# MB9BFD1xT register map
File version: 1.7
Registers are 32-bit, read-write, reset 0x0 unless marked. A register's access mark holds for its fields unless they carry their own. Offsets are from the block's base; [hi:lo] are bit positions; {n}, {i} and the like mark numbered series; 'fields as' and 'values as' point back to an identical list.

## GPIO — General-purpose I/O ports
Base 0x40033000
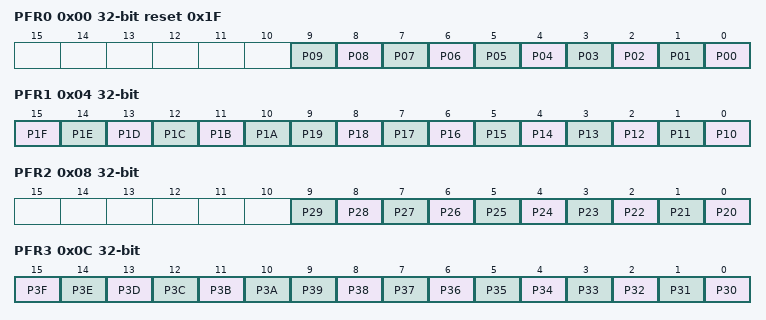
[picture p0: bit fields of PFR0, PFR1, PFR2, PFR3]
0x00 PFR0 reset 0x1F — Port function setting register 0
  [n] P{n:02} (n=0..9) — Bit{n} of PFR0
0x04 PFR1 — Port function setting register 1
  [15] P1F — Bit15 of PFR1
  [14] P1E — Bit14 of PFR1
  [13] P1D — Bit13 of PFR1
  [12] P1C — Bit12 of PFR1
  [11] P1B — Bit11 of PFR1
  [10] P1A — Bit10 of PFR1
  [n-10] P{n} (n=10..19) — Bit{n-10} of PFR1
0x08 PFR2 — Port function setting register 2
  [n-20] P{n} (n=20..29) — Bit{n-20} of PFR2
0x0C PFR3 — Port function setting register 3
  [15] P3F — Bit15 of PFR3
  [14] P3E — Bit14 of PFR3
  [13] P3D — Bit13 of PFR3
  [12] P3C — Bit12 of PFR3
  [11] P3B — Bit11 of PFR3
  [10] P3A — Bit10 of PFR3
  [n-30] P{n} (n=30..39) — Bit{n-30} of PFR3
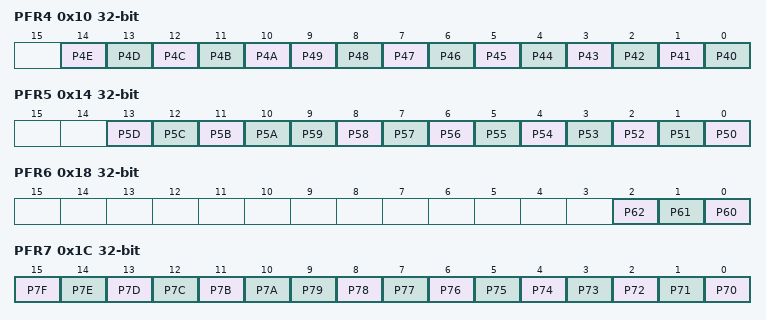
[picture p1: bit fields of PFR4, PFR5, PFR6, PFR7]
0x10 PFR4 — Port function setting register 4
  [14] P4E — Bit14 of PFR4
  [13] P4D — Bit13 of PFR4
  [12] P4C — Bit12 of PFR4
  [11] P4B — Bit11 of PFR4
  [10] P4A — Bit10 of PFR4
  [n-40] P{n} (n=40..49) — Bit{n-40} of PFR4
0x14 PFR5 — Port function setting register 5
  [13] P5D — Bit13 of PFR5
  [12] P5C — Bit12 of PFR5
  [11] P5B — Bit11 of PFR5
  [10] P5A — Bit10 of PFR5
  [n-50] P{n} (n=50..59) — Bit{n-50} of PFR5
0x18 PFR6 — Port function setting register 6
  [2] P62 — Bit2 of PFR6
  [1] P61 — Bit1 of PFR6
  [0] P60 — Bit0 of PFR6
0x1C PFR7 — Port function setting register 7
  [15] P7F — Bit15 of PFR7
  [14] P7E — Bit14 of PFR7
  [13] P7D — Bit13 of PFR7
  [12] P7C — Bit12 of PFR7
  [11] P7B — Bit11 of PFR7
  [10] P7A — Bit10 of PFR7
  [n-70] P{n} (n=70..79) — Bit{n-70} of PFR7
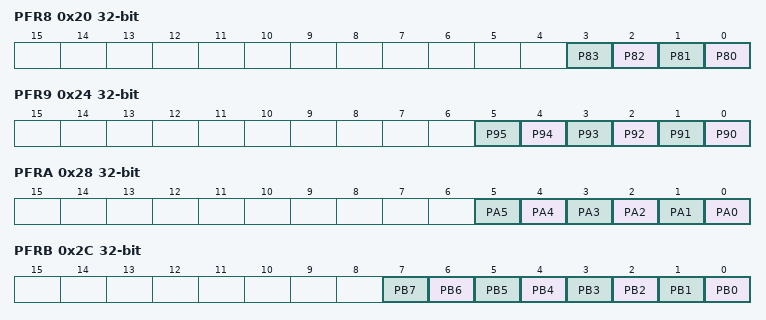
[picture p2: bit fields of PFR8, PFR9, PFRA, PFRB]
0x20 PFR8 — Port function setting register 8
  [n-80] P{n} (n=80..83) — Bit{n-80} of PFR8
0x24 PFR9 — Port function setting register 9
  [n-90] P{n} (n=90..95) — Bit{n-90} of PFR9
0x28 PFRA — Port function setting register A
  [n] PA{n} (n=0..5) — Bit{n} of PFRA
0x2C PFRB — Port function setting register B
  [n] PB{n} (n=0..7) — Bit{n} of PFRB
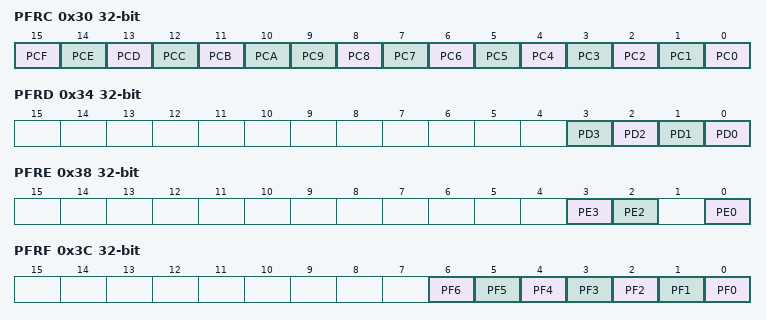
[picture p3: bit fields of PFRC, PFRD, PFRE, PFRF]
0x30 PFRC — Port function setting register C
  [15] PCF — Bit15 of PFRC
  [14] PCE — Bit14 of PFRC
  [13] PCD — Bit13 of PFRC
  [12] PCC — Bit12 of PFRC
  [11] PCB — Bit11 of PFRC
  [10] PCA — Bit10 of PFRC
  [n] PC{n} (n=0..9) — Bit{n} of PFRC
0x34 PFRD — Port function setting register D
  [n] PD{n} (n=0..3) — Bit{n} of PFRD
0x38 PFRE (reset mask 0xB) — Port function setting register E
  [3] PE3 — Bit3 of PFRE
  [2] PE2 — Bit2 of PFRE
  [0] PE0 — Bit0 of PFRE
0x3C PFRF — Port function setting register F
  [n] PF{n} (n=0..6) — Bit{n} of PFRF
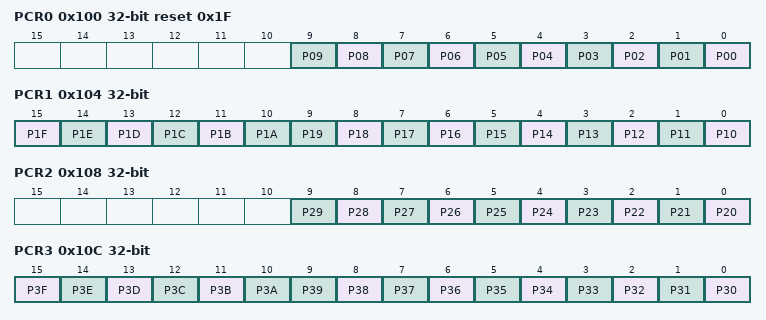
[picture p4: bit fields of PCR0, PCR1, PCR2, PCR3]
0x100 PCR0 reset 0x1F — Pull-up Setting Register 0
  [n] P{n:02} (n=0..9) — Bit{n} of PFR0
0x104 PCR1 — Pull-up Setting Register 1
  fields as PFR1
0x108 PCR2 — Pull-up Setting Register 2
  [n-20] P{n} (n=20..29) — Bit{n-20} of PFR2
0x10C PCR3 — Pull-up Setting Register 3
  fields as PFR3
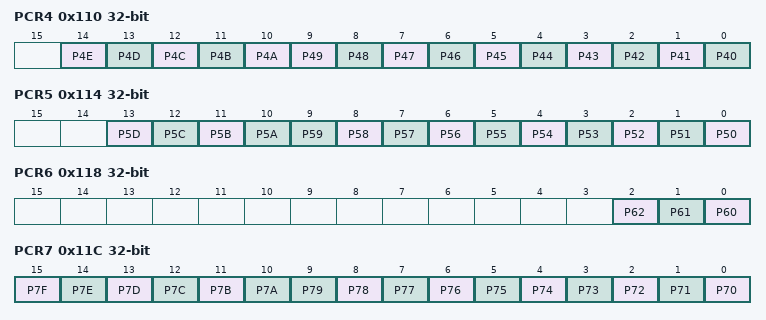
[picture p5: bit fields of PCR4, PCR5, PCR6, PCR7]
0x110 PCR4 — Pull-up Setting Register 4
  fields as PFR4
0x114 PCR5 — Pull-up Setting Register 5
  fields as PFR5
0x118 PCR6 — Pull-up Setting Register 6
  fields as PFR6
0x11C PCR7 — Pull-up Setting Register 7
  fields as PFR7
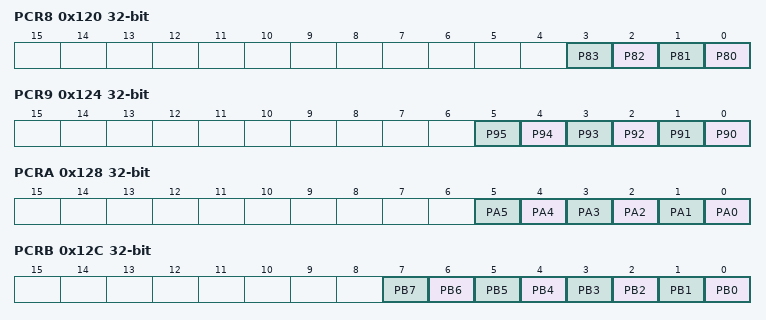
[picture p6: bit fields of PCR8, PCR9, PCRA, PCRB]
0x120 PCR8 — Pull-up Setting Register 8
  [n-80] P{n} (n=80..83) — Bit{n-80} of PFR8
0x124 PCR9 — Pull-up Setting Register 9
  [n-90] P{n} (n=90..95) — Bit{n-90} of PFR9
0x128 PCRA — Pull-up Setting Register A
  [n] PA{n} (n=0..5) — Bit{n} of PFRA
0x12C PCRB — Pull-up Setting Register B
  [n] PB{n} (n=0..7) — Bit{n} of PFRB
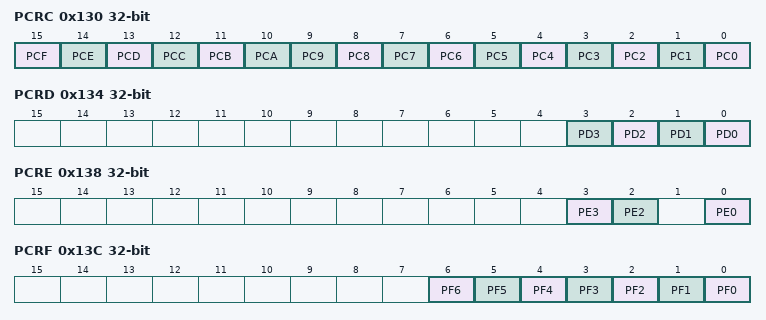
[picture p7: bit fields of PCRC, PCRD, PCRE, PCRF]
0x130 PCRC — Pull-up Setting Register C
  fields as PFRC
0x134 PCRD — Pull-up Setting Register D
  [n] PD{n} (n=0..3) — Bit{n} of PFRD
0x138 PCRE (reset mask 0xB) — Pull-up Setting Register E
  fields as PFRE
0x13C PCRF — Pull-up Setting Register F
  [n] PF{n} (n=0..6) — Bit{n} of PFRF
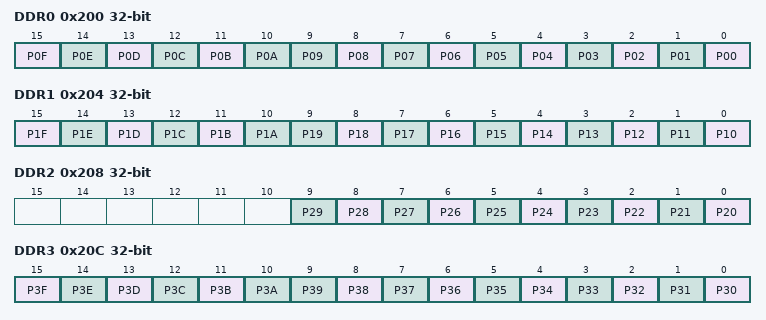
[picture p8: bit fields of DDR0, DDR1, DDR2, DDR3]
0x200 DDR0 — Port input/output direction setting register 0
  [15] P0F — Bit15 of DDR0
  [14] P0E — Bit14 of DDR0
  [13] P0D — Bit13 of DDR0
  [12] P0C — Bit12 of DDR0
  [11] P0B — Bit11 of DDR0
  [10] P0A — Bit10 of DDR0
  [n] P{n:02} (n=0..9) — Bit{n} of DDR0
0x204 DDR1 — Port input/output direction setting register 1
  fields as PFR1
0x208 DDR2 — Port input/output direction setting register 2
  [n-20] P{n} (n=20..29) — Bit{n-20} of PFR2
0x20C DDR3 — Port input/output direction setting register 3
  fields as PFR3
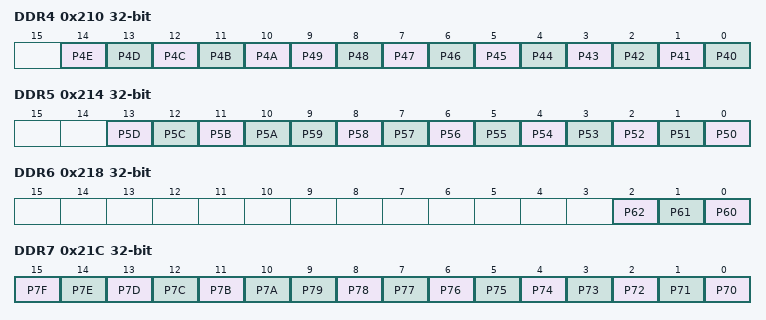
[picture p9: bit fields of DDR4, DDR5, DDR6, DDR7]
0x210 DDR4 — Port input/output direction setting register 4
  fields as PFR4
0x214 DDR5 — Port input/output direction setting register 5
  fields as PFR5
0x218 DDR6 — Port input/output direction setting register 6
  fields as PFR6
0x21C DDR7 — Port input/output direction setting register 7
  fields as PFR7
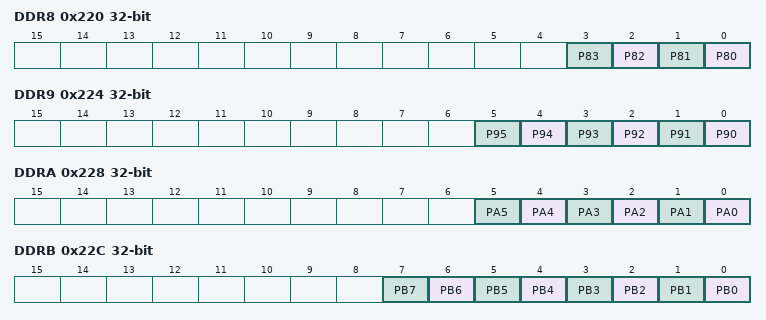
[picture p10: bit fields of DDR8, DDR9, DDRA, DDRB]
0x220 DDR8 — Port input/output direction setting register 8
  [n-80] P{n} (n=80..83) — Bit{n-80} of PFR8
0x224 DDR9 — Port input/output direction setting register 9
  [n-90] P{n} (n=90..95) — Bit{n-90} of PFR9
0x228 DDRA — Port input/output direction setting register A
  [n] PA{n} (n=0..5) — Bit{n} of PFRA
0x22C DDRB — Port input/output direction setting register B
  [n] PB{n} (n=0..7) — Bit{n} of PFRB
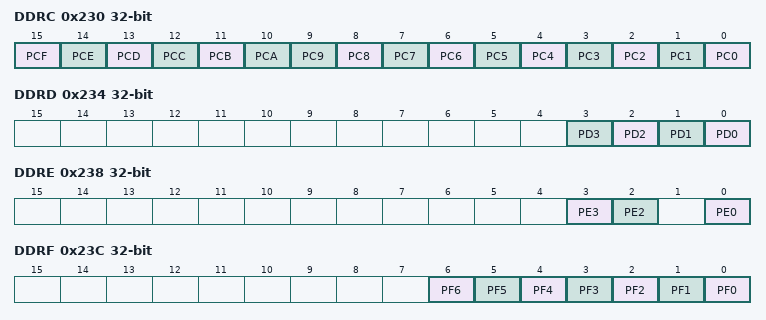
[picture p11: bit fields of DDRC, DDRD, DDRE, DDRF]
0x230 DDRC — Port input/output direction setting register C
  fields as PFRC
0x234 DDRD — Port input/output direction setting register D
  [n] PD{n} (n=0..3) — Bit{n} of PFRD
0x238 DDRE (reset mask 0xB) — Port input/output direction setting register E
  fields as PFRE
0x23C DDRF — Port input/output direction setting register F
  [n] PF{n} (n=0..6) — Bit{n} of PFRF
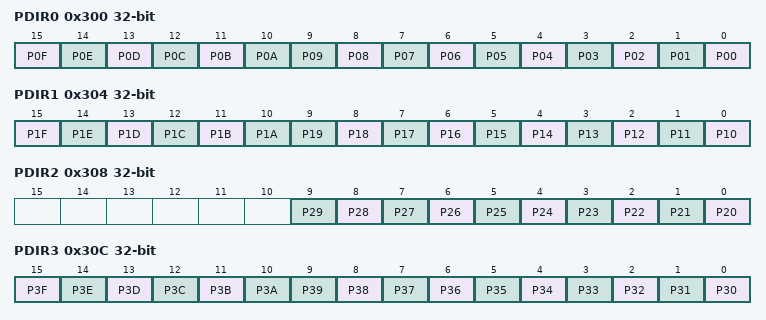
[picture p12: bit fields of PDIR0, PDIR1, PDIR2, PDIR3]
0x300 PDIR0 — Port input data register 0
  fields as DDR0
0x304 PDIR1 — Port input data register 1
  fields as PFR1
0x308 PDIR2 — Port input data register 2
  [n-20] P{n} (n=20..29) — Bit{n-20} of PFR2
0x30C PDIR3 — Port input data register 3
  fields as PFR3
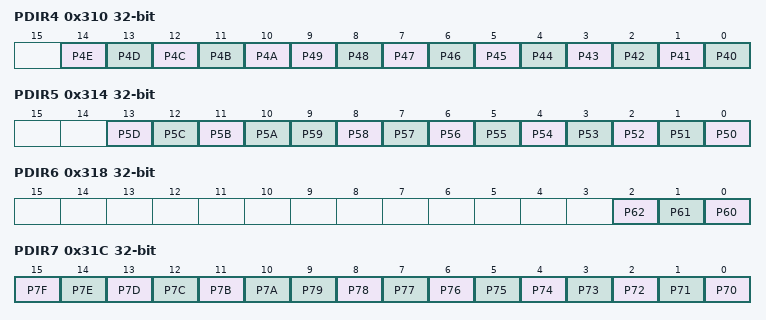
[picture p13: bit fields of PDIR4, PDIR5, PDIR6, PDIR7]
0x310 PDIR4 — Port input data register 4
  fields as PFR4
0x314 PDIR5 — Port input data register 5
  fields as PFR5
0x318 PDIR6 — Port input data register 6
  fields as PFR6
0x31C PDIR7 — Port input data register 7
  fields as PFR7
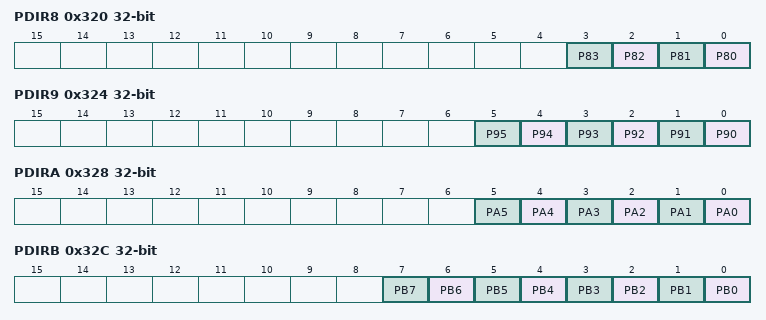
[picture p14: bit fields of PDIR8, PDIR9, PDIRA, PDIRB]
0x320 PDIR8 — Port input data register 8
  [n-80] P{n} (n=80..83) — Bit{n-80} of PFR8
0x324 PDIR9 — Port input data register 9
  [n-90] P{n} (n=90..95) — Bit{n-90} of PFR9
0x328 PDIRA — Port input data register A
  [n] PA{n} (n=0..5) — Bit{n} of PFRA
0x32C PDIRB — Port input data register B
  [n] PB{n} (n=0..7) — Bit{n} of PFRB
0x330 PDIRC — Port input data register C
  fields as PFRC
0x334 PDIRD — Port input data register D
  [n] PD{n} (n=0..3) — Bit{n} of PFRD
0x338 PDIRE (reset mask 0xB) — Port input data register E
  fields as PFRE
0x33C PDIRF — Port input data register F
  [n] PF{n} (n=0..6) — Bit{n} of PFRF
0x400 PDOR0 — Port output data register 0
  fields as DDR0
0x404 PDOR1 — Port output data register 1
  fields as PFR1
0x408 PDOR2 — Port output data register 2
  [n-20] P{n} (n=20..29) — Bit{n-20} of PFR2
0x40C PDOR3 — Port output data register 3
  fields as PFR3
0x410 PDOR4 — Port output data register 4
  fields as PFR4
0x414 PDOR5 — Port output data register 5
  fields as PFR5
0x418 PDOR6 — Port output data register 6
  fields as PFR6
0x41C PDOR7 — Port output data register 7
  fields as PFR7
0x420 PDOR8 — Port output data register 8
  [n-80] P{n} (n=80..83) — Bit{n-80} of PFR8
0x424 PDOR9 — Port output data register 9
  [n-90] P{n} (n=90..95) — Bit{n-90} of PFR9
0x428 PDORA — Port output data register A
  [n] PA{n} (n=0..5) — Bit{n} of PFRA
0x42C PDORB — Port output data register B
  [n] PB{n} (n=0..7) — Bit{n} of PFRB
0x430 PDORC — Port output data register C
  fields as PFRC
0x434 PDORD — Port output data register D
  [n] PD{n} (n=0..3) — Bit{n} of PFRD
0x438 PDORE (reset mask 0xB) — Port output data register E
  fields as PFRE
0x43C PDORF — Port output data register F
  [n] PF{n} (n=0..6) — Bit{n} of PFRF
0x500 ADE reset 0xFFFFFFFF — Analog input setting register
  [n] AN{n} (n=0..31) — Bit{n} of ADE
0x580 SPSR reset 0x5 — Special port setting register
  [5] USB1C — USBch1 pin setting bit
  [4] USB0C — USBch0 pin setting bit
  [2] MAINXC — Main clock(oscillation) pin setting bit
  [0] SUBXC — Sub clock(oscillation) pin setting bit
0x600 EPFR00 reset 0x30000 (reset mask 0x303022C7) — Extended pin function setting register 00
  [25] TRC1E — TRACED function select bit1
  [24] TRC0E — TRACED function select bit0
  [17] JTAGEN1S — JTAG function select bit1
  [16] JTAGEN0B — JTAG function select bit0
  [13] USBP1E — USBch1 function select bit
  [9] USBP0E — USBch0 function select bit
  [7:6] SUBOUTE — Sub clock divide output function select bit
  [2:1] CROUTE — Internal high-speed CR oscillation output function select bit
  [0] NMIS — NMIX function select bit
0x604 EPFR01 — Extended pin function setting register 01
  [3n+22:3n+20] IC{n:02}S (n=0..3) — IC{n:02} input select bit
  [19:18] FRCK0S — FRCK0 input select bit
  [17:16] DTTI0S — DTTIX0 input select bit
  [12] DTTI0C — DTTIX0 function select bit
  [2n+1:2n] RTO{n:02}E (n=0..5) — RTO{n:02}E output select bit
0x608 EPFR02 — Extended pin function setting register 02
  [3n-8:3n-10] IC{n}S (n=10..13) — IC{n} input select bit
  [19:18] FRCK1S — FRCK1 input select bit
  [17:16] DTTI1S — DTTIX1 input select bit
  [12] DTTI1C — DTTIX1 function select bit
  [2n-19:2n-20] RTO{n}E (n=10..15) — RTO{n}E output select bit
0x60C EPFR03 — Extended pin function setting register 03
  [3n-38:3n-40] IC{n}S (n=20..23) — IC{n} input select bit
  [19:18] FRCK2S — FRCK2 input select bit
  [17:16] DTTI2S — DTTIX2 input select bit
  [12] DTTI2C — DTTIX2 function select bit
  [2n-39:2n-40] RTO{n}E (n=20..25) — RTO{n}E output select bit
0x610 EPFR04 — Extended pin function setting register 04
  [8n+5:8n+4] TIOB{n}S (n=0..3) — TIOB{n} input select bit
  [27:26] TIOA3E — TIOA3E output select bit
  [25:24] TIOA3S — TIOA3 input select bit
  [19:18] TIOA2E — TIOA2 output select bit
  [11:10] TIOA1E — TIOA1E output select bit
  [9:8] TIOA1S — TIOA1 input select bit
  [3:2] TIOA0E — TIOA0 output select bit
0x614 EPFR05 — Extended pin function setting register 05
  [29:28] TIOB7S — TIOB7 input select Bit
  [27:26] TIOA7E — TIOA7E output select bit
  [25:24] TIOA7S — TIOA7 input select bit
  [21:20] TIOB6S — TIOB6 input select bit
  [19:18] TIOA6E — TIOA6 output select bit
  [13:12] TIOB5S — TIOB5 input select bit
  [11:10] TIOA5E — TIOA5E output select bit
  [9:8] TIOA5S — TIOA5 input select bit
  [5:4] TIOB4S — TIOB4 input select bit
  [3:2] TIOA4E — TIOA4 output select bit
0x618 EPFR06 — Extended pin function setting register 06
  [2n+1:2n] EINT{n:02}S (n=0..15) — External interrupt {n} input select bit
0x61C EPFR07 — Extended pin function setting register 07
  [6n+9:6n+8] SCK{n}B (n=0..3) — SCK{n} input/output select bit
  [25:24] SOT3B — SOT3B input/output select bit
  [6n+5:6n+4] SIN{n}S (n=0..3) — SIN{n}S input select bit
  [19:18] SOT2B — SOT2B input/output select bit
  [13:12] SOT1B — SCK1B input/output select bit
  [7:6] SOT0B — SOT0B input/output select bit
0x620 EPFR08 — Extended pin function setting register 08
  [6n-15:6n-16] SCK{n}B (n=4..7) — SCK{n} input/output select bit
  [6n-17:6n-18] SOT{n}B (n=4..7) — SOT{n}B input/output select bit
  [6n-19:6n-20] SIN{n}S (n=4..7) — SIN{n}S input select bit
  [3:2] CTS4S — CTS4S input select bit
  [1:0] RTS4E — RTS4E output select bit
0x624 EPFR09 — Extended pin function setting register 09
  [31:30] CTX1E — CAN TX1 Output Select bits
  [29:28] CRX1S — CAN RX1 Input Select bits
  [27:26] CTX0E — CAN TX2 Output Select bits
  [25:24] CRX0S — CAN RX2 Input Select bits
  [23:20] ADTRG2S — ADTRG2 input select bit
  [19:16] ADTRG1S — ADTRG1 input select bit
  [15:12] ADTRG0S — ADTRG0 input select bit
  [11:10] QZIN1S — QZIN1S input select bit
  [9:8] QBIN1S — QBIN1S input select bit
  [7:6] QAIN1S — QAIN1S input select bit
  [5:4] QZIN0S — QZIN0S input select bit
  [3:2] QBIN0S — QBIN0S input select bit
  [1:0] QAIN0S — QAIN0S input select bit
0x628 EPFR10 — Extended pin function setting register 10
  [n+7] UEA{n:02}E (n=8..24) — UEA{n:02}E output select bit
  [14] UEAOOE — UEAOOE output select bit
  [n+6] UECS{n}E (n=1..7) — UECS{n}E output select bit
  [6] UEFLSE — UEFLSE output select bit
  [5] UEOEXE — UEOEXE output select bit
  [4] UEDQME — UEDQME output select bit
  [3] UEWEXE — UEWEXE output select bit
  [2] UECLKE — UECLKE output select bit
  [1] UEDTHB — UEDTHB input/output select bit
  [0] UEDEFB — UEDEFB input/output select bit
0x62C EPFR11 — Extended pin function setting register 11
  [25] UERLC — UERLC relocation select bit
  [24] UED15B — UED15B input/output select bit
  [n+9] UED{n:02}B (n=0..14) — UED{n:02}B output select bit
  [n+1] UEA{n:02}E (n=1..7) — UEA{n:02}E output select bit
  [1] UECS0E — UECS0E output select bit
  [0] UEALEE — UEALEE output select bit
0x630 EPFR12 — Extended pin function setting register 12
  [8n-59:8n-60] TIOB{n}S (n=8..11) — TIOB{n} Input Select bits
  [8n-61:8n-62] TIOA{n}E (n=8..11) — TIOA{n} Output Select bits
  [25:24] TIOA11S — TIOA11 Input Select bits
  [9:8] TIOA9S — TIOA9 Input Select bits
0x634 EPFR13 — Extended pin function setting register 13
  [8n-91:8n-92] TIOB{n}S (n=12..15) — TIOB{n} Input Select bits
  [8n-93:8n-94] TIOA{n}E (n=12..15) — TIOA{n} Output Select bits
  [25:24] TIOA15S — TIOA15 Input Select bits
  [9:8] TIOA13S — TIOA13 Input Select bits
0x638 EPFR14 — Extended pin function setting register 14
  [29:28] E_SPLC — Input cutoff Select bit in Standby of input Pin for Ethernet
  [27] E_PSE — PPS0_PPS1 Output Select bit for Ethernet
  [26] E_CKE — E_COUT Output Select bit
  [25] E_MD1B — E_MDO1 I/O Select bit
  [24] E_MD0B — E_MDO0 I/O Select bit
  [23] E_MC1B — E_MDC1 I/O Select bit
  [22] E_MC0E — E_MDC0 Output Select bit
  [21] E_TE1E — E_TXER0_TXEN1 Output Select bit
  [20] E_TE0E — E_TXEN0 Output Select bit
  [19] E_TD1E — "E_TX02_TX10, E_TX03_TX11 Output Select bit "
  [18] E_TD0E — "E_TX00, E_TX01 Output Select bit "
  [5:4] QZIN2S — QDU-ch.2 ZIN Input Pin bits
  [3:2] QBIN2S — QDU-ch.2 BIN Input Pin bits
  [1:0] QAIN2S — QDU-ch.2 AIN Input Pin bits
0x63C EPFR15 — Extended pin function setting register 15
  [2n-31:2n-32] EINT{n}S (n=16..31) — External interrupt {n} input select bit
0x700 PZR0 — Port Pseudo Open Drain Setting Register 0
  fields as DDR0
0x704 PZR1 — Port Pseudo Open Drain Setting Register 1
  fields as PFR1
0x708 PZR2 — Port Pseudo Open Drain Setting Register 2
  [n-20] P{n} (n=20..29) — Bit{n-20} of PFR2
0x70C PZR3 — Port Pseudo Open Drain Setting Register 3
  fields as PFR3
0x710 PZR4 — Port Pseudo Open Drain Setting Register 4
  fields as PFR4
0x714 PZR5 — Port Pseudo Open Drain Setting Register 5
  fields as PFR5
0x718 PZR6 — Port Pseudo Open Drain Setting Register 6
  fields as PFR6
0x71C PZR7 — Port Pseudo Open Drain Setting Register 7
  fields as PFR7
0x720 PZR8 — Port Pseudo Open Drain Setting Register 8
  [n-80] P{n} (n=80..83) — Bit{n-80} of PFR8
0x724 PZR9 — Port Pseudo Open Drain Setting Register 9
  [n-90] P{n} (n=90..95) — Bit{n-90} of PFR9
0x728 PZRA — Port Pseudo Open Drain Setting Register A
  [n] PA{n} (n=0..5) — Bit{n} of PFRA
0x72C PZRB — Port Pseudo Open Drain Setting Register B
  [n] PB{n} (n=0..7) — Bit{n} of PFRB
0x730 PZRC — Port Pseudo Open Drain Setting Register C
  fields as PFRC
0x734 PZRD — Port Pseudo Open Drain Setting Register D
  [n] PD{n} (n=0..3) — Bit{n} of PFRD
0x738 PZRE (reset mask 0xB) — Port Pseudo Open Drain Setting Register E
  fields as PFRE
0x73C PZRF — Port Pseudo Open Drain Setting Register F
  [n] PF{n} (n=0..6) — Bit{n} of PFRF
